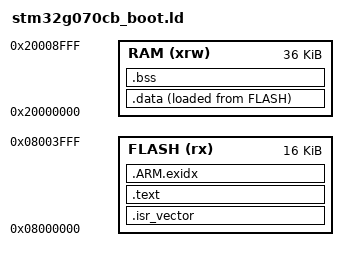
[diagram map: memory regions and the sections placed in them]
/* Linker script: Stepwhere bootloader, first 16 KB of STM32G070CB flash. */
ENTRY(Reset_Handler)

MEMORY
{
  FLASH (rx)  : ORIGIN = 0x08000000, LENGTH = 16K
  RAM   (xrw) : ORIGIN = 0x20000000, LENGTH = 36K
}

_estack = ORIGIN(RAM) + LENGTH(RAM);

SECTIONS
{
  .isr_vector : { KEEP(*(.isr_vector)) } > FLASH

  .text :
  {
    *(.text*)
    *(.rodata*)
    . = ALIGN(4);
  } > FLASH

  .ARM.exidx : { *(.ARM.exidx*) } > FLASH

  _sidata = LOADADDR(.data);
  .data :
  {
    . = ALIGN(4);
    _sdata = .;
    *(.data*)
    . = ALIGN(4);
    _edata = .;
  } > RAM AT > FLASH

  .bss (NOLOAD) :
  {
    . = ALIGN(4);
    _sbss = .;
    *(.bss*)
    *(COMMON)
    . = ALIGN(4);
    _ebss = .;
  } > RAM

  /* Keep 2 KB for the stack. */
  ASSERT(_ebss + 2048 <= _estack, "bootloader RAM overflow")
}
